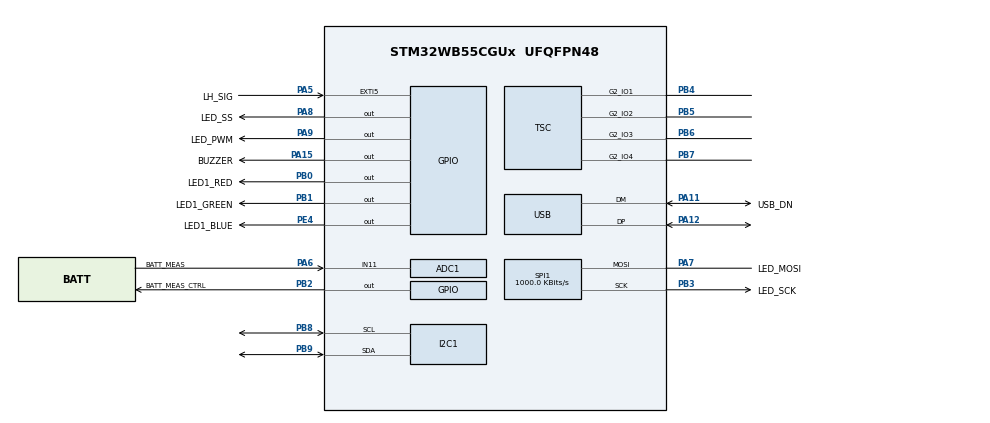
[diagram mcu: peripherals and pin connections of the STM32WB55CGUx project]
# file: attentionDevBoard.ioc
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ADC1.Channel-0\#ChannelRegularConversion=ADC_CHANNEL_11
ADC1.NbrOfConversionFlag=1
ADC1.OffsetNumber-0\#ChannelRegularConversion=ADC_OFFSET_NONE
ADC1.Rank-0\#ChannelRegularConversion=1
ADC1.SamplingTime-0\#ChannelRegularConversion=ADC_SAMPLETIME_2CYCLES_5
ADC1.master=1
FREERTOS.Tasks01=defaultTask,0,128,StartDefaultTask,Default,NULL
FREERTOS.configTOTAL_HEAP_SIZE=6072
I2C1.Timeout=0x0000830D
I2C1.Timing=0x10707DBC
Mcu.Family=STM32WB
Mcu.Name=STM32WB55CGUx
Mcu.Package=UFQFPN48
NVIC.I2C1_EV_IRQn=true\:5\:0\:false\:false\:true\:true\:true\:true
NVIC.PriorityGroup=NVIC_PRIORITYGROUP_4
NVIC.TIM1_UP_TIM16_IRQn=true\:0\:0\:false\:false\:true\:false\:false\:true
NVIC.TSC_IRQn=true\:5\:0\:false\:false\:true\:true\:true\:true
NVIC.TimeBase=TIM1_UP_TIM16_IRQn
NVIC.TimeBaseIP=TIM1
OSC_IN.Mode=HSE-External-Oscillator
OSC_IN.Signal=RCC_OSC_IN
OSC_OUT.Mode=HSE-External-Oscillator
OSC_OUT.Signal=RCC_OSC_OUT
PA11.GPIO_Label=USB_DN
PA11.Mode=Device
PA11.Signal=USB_DM
PA12.Mode=Device
PA12.Signal=USB_DP
PA13.Mode=Serial_Wire
PA13.Signal=SYS_JTMS-SWDIO
PA14.Mode=Serial_Wire
PA14.Signal=SYS_JTCK-SWCLK
PA15.GPIO_Label=BUZZER
PA15.Signal=GPIO_Output
PA5.GPIO_Label=LH_SIG
PA5.Signal=GPXTI5
PA6.GPIO_Label=BATT_MEAS
PA6.Signal=ADCx_IN11
PA7.GPIO_Label=LED_MOSI
PA7.Mode=Simplex_Bidirectional_Master
PA7.Signal=SPI1_MOSI
PA8.GPIO_Label=LED_SS
PA8.Signal=GPIO_Output
PA9.GPIO_Label=LED_PWM
PA9.Signal=GPIO_Output
PB0.GPIO_Label=LED1_RED
PB0.PinState=GPIO_PIN_SET
PB0.Signal=GPIO_Output
PB1.GPIO_Label=LED1_GREEN
PB1.GPIO_ModeDefaultOutputPP=GPIO_MODE_OUTPUT_OD
PB1.PinState=GPIO_PIN_SET
PB1.Signal=GPIO_Output
PB2.GPIO_Label=BATT_MEAS_CTRL
PB2.GPIO_ModeDefaultOutputPP=GPIO_MODE_OUTPUT_OD
PB2.GPIO_PuPd=GPIO_NOPULL
PB2.PinState=GPIO_PIN_SET
PB2.Signal=GPIO_Output
PB3.GPIO_Label=LED_SCK
PB3.Mode=Simplex_Bidirectional_Master
PB3.Signal=SPI1_SCK
PB4.Mode=G2_IO1-Sampling
PB4.Signal=TSC_G2_IO1
PB5.Mode=G2_IO2-Channel
PB5.Signal=TSC_G2_IO2
PB6.Mode=G2_IO3-Channel
PB6.Signal=TSC_G2_IO3
PB7.Mode=G2_IO4-Channel
PB7.Signal=TSC_G2_IO4
PB8.Mode=I2C
PB8.Signal=I2C1_SCL
PB9.Mode=I2C
PB9.Signal=I2C1_SDA
PC14-OSC32_IN.Mode=LSE-External-Oscillator
PC14-OSC32_IN.Signal=RCC_OSC32_IN
PC15-OSC32_OUT.Mode=LSE-External-Oscillator
PC15-OSC32_OUT.Signal=RCC_OSC32_OUT
PE4.GPIO_Label=LED1_BLUE
PE4.PinState=GPIO_PIN_SET
PE4.Signal=GPIO_Output
ProjectManager.HeapSize=0x200
ProjectManager.StackSize=0x400
ProjectManager.TargetToolchain=TrueSTUDIO
RCC.ADCFreq_Value=48000000
RCC.AHB2CLKDivider=RCC_SYSCLK_DIV2
RCC.AHBFreq_Value=64000000
RCC.APB1Freq_Value=64000000
RCC.APB1TimFreq_Value=64000000
RCC.APB2Freq_Value=64000000
RCC.APB2TimFreq_Value=64000000
RCC.APB3Freq_Value=16000000
RCC.CortexFreq_Value=64000000
RCC.HCLKFreq_Value=64000000
RCC.HSE_VALUE=32000000
RCC.HSI48_VALUE=48000000
RCC.HSI_VALUE=16000000
RCC.PLLN=32
RCC.PLLSAI1N=24
RCC.SYSCLKFreq_VALUE=64000000
RCC.SYSCLKSource=RCC_SYSCLKSOURCE_PLLCLK
RCC.USBFreq_Value=48000000
RCC.VCOOutputFreq_Value=128000000
RF1.Mode=RF1_Activate
RF1.Signal=RF_RF1
SH.ADCx_IN11.0=ADC1_IN11,IN11-Single-Ended
SPI1.BaudRatePrescaler=SPI_BAUDRATEPRESCALER_64
SPI1.CLKPhase=SPI_PHASE_2EDGE
SPI1.CLKPolarity=SPI_POLARITY_HIGH
SPI1.CalculateBaudRate=1000.0 KBits/s
SPI1.DataSize=SPI_DATASIZE_8BIT
SPI1.Direction=SPI_DIRECTION_1LINE
SPI1.Mode=SPI_MODE_MASTER
SPI1.VirtualType=VM_MASTER
TOUCHSENSING.IO_3CH_LIN_M1_B_NBR1_CH1=G2_IO2
TOUCHSENSING.IO_3CH_LIN_M1_B_NBR1_CH2=G2_IO3
TOUCHSENSING.IO_3CH_LIN_M1_B_NBR1_CH3=G2_IO4
TOUCHSENSING.TSLPRM_SENSORS_DATAS=TSLPRM_USE_3CH_LIN_M1_B_NBR1 3 1 1 1 
TOUCHSENSING.TSLPRM_USE_3CH_LIN_M1=1
TOUCHSENSING.TSLPRM_USE_3CH_LIN_M1_B_NBR=1
TSC.CTPulseHighLength=TSC_CTPH_1CYCLE
TSC.CTPulseLowLength=TSC_CTPL_1CYCLE
TSC.ChannelIOs-G2_IO2=TSC_GROUP2_IO2
TSC.ChannelIOs-G2_IO2-Channel=TSC_GROUP2_IO2
TSC.ChannelIOs-G2_IO3=TSC_GROUP2_IO3
TSC.ChannelIOs-G2_IO3-Channel=TSC_GROUP2_IO3
TSC.ChannelIOs-G2_IO4=TSC_GROUP2_IO4
TSC.ChannelIOs-G2_IO4-Channel=TSC_GROUP2_IO4
TSC.MaxCountValue=TSC_MCV_511
TSC.SamplingIOs=TSC_GROUP2_IO1
TSC.SpreadSpectrum=DISABLE
VP_FREERTOS_VS_CMSIS_V1.Mode=CMSIS_V1
VP_SYS_VS_tim1.Mode=TIM1
VP_TOUCHSENSING_VS_TOUCHSENSING.Mode=TouchSensing_Enabled
board=custom

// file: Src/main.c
/* USER CODE BEGIN Header */
/**
  ******************************************************************************
  * @file           : main.c
  * @brief          : Main program body
  ******************************************************************************
  * @attention
  *
  * <h2><center>&copy; Copyright (c) 2019 STMicroelectronics.
  * All rights reserved.</center></h2>
  *
  * This software component is licensed by ST under BSD 3-Clause license,
  * the "License"; You may not use this file except in compliance with the
  * License. You may obtain a copy of the License at:
  *                        opensource.org/licenses/BSD-3-Clause
  *
  ******************************************************************************
  */
/* USER CODE END Header */

#include "main.h"
#include "cmsis_os.h"
#include "adc.h"
#include "i2c.h"
#include "rf.h"
#include "spi.h"
#include "touchsensing.h"
#include "tsc.h"
#include "usb.h"
#include "gpio.h"

void SystemClock_Config(void);
void MX_FREERTOS_Init(void);

int main(void)
{

  /* MCU Configuration--------------------------------------------------------*/

  /* Reset of all peripherals, Initializes the Flash interface and the Systick. */
  HAL_Init();

  /* Configure the system clock */
  SystemClock_Config();

  /* Initialize all configured peripherals */
  MX_GPIO_Init();
  MX_ADC1_Init();
  MX_I2C1_Init();
  MX_RF_Init();
  MX_TSC_Init();
  MX_USB_PCD_Init();
  MX_SPI1_Init();

  /* Call init function for freertos objects (in freertos.c) */
  MX_FREERTOS_Init();

  /* Start scheduler */
  osKernelStart();

  /* We should never get here as control is now taken by the scheduler */

  /* Infinite loop */
  while (1)
  {

  }
}

void SystemClock_Config(void)
{
  RCC_OscInitTypeDef RCC_OscInitStruct = {0};
  RCC_ClkInitTypeDef RCC_ClkInitStruct = {0};
  RCC_PeriphCLKInitTypeDef PeriphClkInitStruct = {0};

  /** Configure LSE Drive Capability
  */
  __HAL_RCC_LSEDRIVE_CONFIG(RCC_LSEDRIVE_LOW);
  /** Configure the main internal regulator output voltage
  */
  __HAL_PWR_VOLTAGESCALING_CONFIG(PWR_REGULATOR_VOLTAGE_SCALE1);
  /** Initializes the CPU, AHB and APB busses clocks
  */
  RCC_OscInitStruct.OscillatorType = RCC_OSCILLATORTYPE_HSI|RCC_OSCILLATORTYPE_LSI1
                              |RCC_OSCILLATORTYPE_HSE|RCC_OSCILLATORTYPE_LSE
                              |RCC_OSCILLATORTYPE_MSI;
  RCC_OscInitStruct.HSEState = RCC_HSE_ON;
  RCC_OscInitStruct.LSEState = RCC_LSE_ON;
  RCC_OscInitStruct.HSIState = RCC_HSI_ON;
  RCC_OscInitStruct.MSIState = RCC_MSI_ON;
  RCC_OscInitStruct.HSICalibrationValue = RCC_HSICALIBRATION_DEFAULT;
  RCC_OscInitStruct.MSICalibrationValue = RCC_MSICALIBRATION_DEFAULT;
  RCC_OscInitStruct.MSIClockRange = RCC_MSIRANGE_6;
  RCC_OscInitStruct.LSIState = RCC_LSI_ON;
  RCC_OscInitStruct.PLL.PLLState = RCC_PLL_ON;
  RCC_OscInitStruct.PLL.PLLSource = RCC_PLLSOURCE_MSI;
  RCC_OscInitStruct.PLL.PLLM = RCC_PLLM_DIV1;
  RCC_OscInitStruct.PLL.PLLN = 32;
  RCC_OscInitStruct.PLL.PLLP = RCC_PLLP_DIV2;
  RCC_OscInitStruct.PLL.PLLR = RCC_PLLR_DIV2;
  RCC_OscInitStruct.PLL.PLLQ = RCC_PLLQ_DIV2;
  if (HAL_RCC_OscConfig(&RCC_OscInitStruct) != HAL_OK)
  {
    Error_Handler();
  }
  /** Configure the SYSCLKSource, HCLK, PCLK1 and PCLK2 clocks dividers
  */
  RCC_ClkInitStruct.ClockType = RCC_CLOCKTYPE_HCLK4|RCC_CLOCKTYPE_HCLK2
                              |RCC_CLOCKTYPE_HCLK|RCC_CLOCKTYPE_SYSCLK
                              |RCC_CLOCKTYPE_PCLK1|RCC_CLOCKTYPE_PCLK2;
  RCC_ClkInitStruct.SYSCLKSource = RCC_SYSCLKSOURCE_PLLCLK;
  RCC_ClkInitStruct.AHBCLKDivider = RCC_SYSCLK_DIV1;
  RCC_ClkInitStruct.APB1CLKDivider = RCC_HCLK_DIV1;
  RCC_ClkInitStruct.APB2CLKDivider = RCC_HCLK_DIV1;
  RCC_ClkInitStruct.AHBCLK2Divider = RCC_SYSCLK_DIV2;
  RCC_ClkInitStruct.AHBCLK4Divider = RCC_SYSCLK_DIV1;

  if (HAL_RCC_ClockConfig(&RCC_ClkInitStruct, FLASH_LATENCY_3) != HAL_OK)
  {
    Error_Handler();
  }
  /** Initializes the peripherals clocks
  */
  PeriphClkInitStruct.PeriphClockSelection = RCC_PERIPHCLK_SMPS|RCC_PERIPHCLK_RFWAKEUP
                              |RCC_PERIPHCLK_I2C1|RCC_PERIPHCLK_USB
                              |RCC_PERIPHCLK_ADC;
  PeriphClkInitStruct.PLLSAI1.PLLN = 24;
  PeriphClkInitStruct.PLLSAI1.PLLP = RCC_PLLP_DIV2;
  PeriphClkInitStruct.PLLSAI1.PLLQ = RCC_PLLQ_DIV2;
  PeriphClkInitStruct.PLLSAI1.PLLR = RCC_PLLR_DIV2;
  PeriphClkInitStruct.PLLSAI1.PLLSAI1ClockOut = RCC_PLLSAI1_USBCLK|RCC_PLLSAI1_ADCCLK;
  PeriphClkInitStruct.I2c1ClockSelection = RCC_I2C1CLKSOURCE_PCLK1;
  PeriphClkInitStruct.UsbClockSelection = RCC_USBCLKSOURCE_PLLSAI1;
  PeriphClkInitStruct.AdcClockSelection = RCC_ADCCLKSOURCE_PLLSAI1;
  PeriphClkInitStruct.RFWakeUpClockSelection = RCC_RFWKPCLKSOURCE_LSI;
  PeriphClkInitStruct.SmpsClockSelection = RCC_SMPSCLKSOURCE_HSE;
  PeriphClkInitStruct.SmpsDivSelection = RCC_SMPSCLKDIV_RANGE0;

  if (HAL_RCCEx_PeriphCLKConfig(&PeriphClkInitStruct) != HAL_OK)
  {
    Error_Handler();
  }
  /** Enable MSI Auto calibration
  */
  HAL_RCCEx_EnableMSIPLLMode();
}

/* USER CODE BEGIN 4 */
uint8_t temp_var = 0;
void HAL_TSC_ConvCpltCallback(TSC_HandleTypeDef *htsc)
{
  /* Prevent unused argument(s) compilation warning */
  if (HAL_TSC_GroupGetStatus(htsc, TSC_GROUP2_IDX) == TSC_GROUP_COMPLETED){
    temp_var = HAL_TSC_GroupGetValue(htsc, TSC_GROUP2_IDX);
    if(temp_var <= 100){
      HAL_GPIO_TogglePin(LED1_BLUE_GPIO_Port, LED1_BLUE_Pin);
    }
  }

//  TSC_GROUP2_IO2
//  TSC_GROUP2_IO3
//  TSC_GROUP2_IO4
  /* NOTE : This function should not be modified, when the callback is needed,
            the HAL_TSC_ConvCpltCallback could be implemented in the user file.
   */
}
/* USER CODE END 4 */

void HAL_TIM_PeriodElapsedCallback(TIM_HandleTypeDef *htim)
{
  if (htim->Instance == TIM1) {
    HAL_IncTick();
  }
}

void Error_Handler(void)
{
}

/************************ (C) COPYRIGHT STMicroelectronics *****END OF FILE****/
